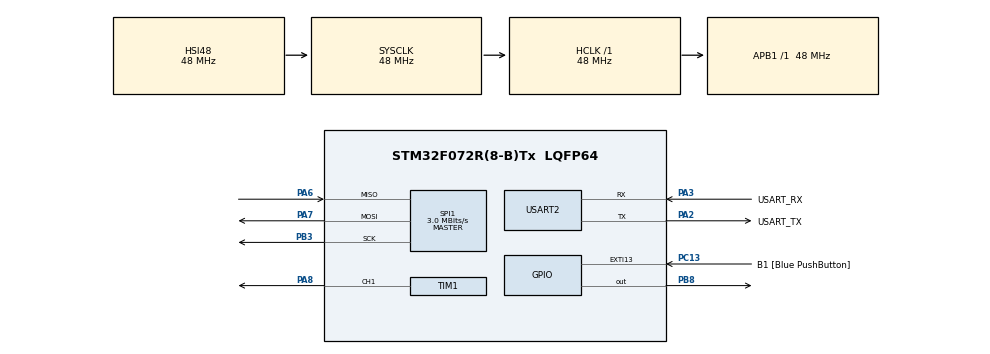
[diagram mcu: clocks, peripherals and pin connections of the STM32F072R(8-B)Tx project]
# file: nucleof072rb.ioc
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Mcu.Family=STM32F0
Mcu.Name=STM32F072R(8-B)Tx
Mcu.Package=LQFP64
PA13.GPIO_Label=TMS
PA13.Mode=Serial_Wire
PA13.Signal=SYS_SWDIO
PA14.GPIO_Label=TCK
PA14.Mode=Serial_Wire
PA14.Signal=SYS_SWCLK
PA2.GPIO_Label=USART_TX
PA2.GPIO_Mode=GPIO_MODE_AF_PP
PA2.GPIO_PuPd=GPIO_NOPULL
PA2.GPIO_Speed=GPIO_SPEED_FREQ_LOW
PA2.Mode=Asynchronous
PA2.Signal=USART2_TX
PA3.GPIO_Label=USART_RX
PA3.GPIO_Mode=GPIO_MODE_AF_PP
PA3.GPIO_PuPd=GPIO_NOPULL
PA3.GPIO_Speed=GPIO_SPEED_FREQ_LOW
PA3.Mode=Asynchronous
PA3.Signal=USART2_RX
PA6.Mode=Full_Duplex_Master
PA6.Signal=SPI1_MISO
PA7.Mode=Full_Duplex_Master
PA7.Signal=SPI1_MOSI
PA8.Signal=S_TIM1_CH1
PB3.Mode=Full_Duplex_Master
PB3.Signal=SPI1_SCK
PB8.Signal=GPIO_Output
PC13.GPIO_Label=B1 [Blue PushButton]
PC13.GPIO_ModeDefaultEXTI=GPIO_MODE_IT_FALLING
PC13.Signal=GPXTI13
PC14-OSC32_IN.Mode=LSE-External-Oscillator
PC14-OSC32_IN.Signal=RCC_OSC32_IN
PC15-OSC32_OUT.Mode=LSE-External-Oscillator
PC15-OSC32_OUT.Signal=RCC_OSC32_OUT
PF0-OSC_IN.Mode=HSE-External-Clock-Source
PF0-OSC_IN.Signal=RCC_OSC_IN
PF1-OSC_OUT.Signal=RCC_OSC_OUT
ProjectManager.HeapSize=0x200
ProjectManager.StackSize=0x400
ProjectManager.TargetToolchain=STM32CubeIDE
RCC.AHBFreq_Value=48000000
RCC.APB1Freq_Value=48000000
RCC.APB1TimFreq_Value=48000000
RCC.FLatency-AdvancedSettings=FLASH_LATENCY_1
RCC.HCLKFreq_Value=48000000
RCC.PLLDivider=RCC_PREDIV_DIV2
RCC.PLLMUL=RCC_PLL_MUL12
RCC.PREFETCH_ENABLE-AdvancedSettings=1
RCC.SYSCLKFreq_VALUE=48000000
RCC.SYSCLKSource=RCC_SYSCLKSOURCE_HSI48
SH.S_TIM1_CH1.0=TIM1_CH1,PWM Generation1 CH1
SPI1.BaudRatePrescaler=SPI_BAUDRATEPRESCALER_16
SPI1.CalculateBaudRate=3.0 MBits/s
SPI1.DataSize=SPI_DATASIZE_8BIT
SPI1.Direction=SPI_DIRECTION_2LINES
SPI1.Mode=SPI_MODE_MASTER
SPI1.VirtualType=VM_MASTER
TIM1.Channel-PWM\ Generation1\ CH1=TIM_CHANNEL_1
TIM1.Period=64000
TIM1.Prescaler=14
USART2.VirtualMode=VM_ASYNC
USART2.VirtualMode-Asynchronous=VM_ASYNC
VP_TIM1_VS_ClockSourceINT.Mode=Internal
board=NUCLEO-F072RB

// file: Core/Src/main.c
/* USER CODE BEGIN Header */
/**
  ******************************************************************************
  * @file           : main.c
  * @brief          : Main program body
  ******************************************************************************
  * @attention
  *
  * <h2><center>&copy; Copyright (c) 2021 STMicroelectronics.
  * All rights reserved.</center></h2>
  *
  * This software component is licensed by ST under BSD 3-Clause license,
  * the "License"; You may not use this file except in compliance with the
  * License. You may obtain a copy of the License at:
  *                        opensource.org/licenses/BSD-3-Clause
  *
  ******************************************************************************
  */
/* USER CODE END Header */
#include "main.h"
#include "spi.h"
#include "tim.h"
#include "usart.h"
#include "gpio.h"

void SystemClock_Config(void);

int main(void)
{
  /* USER CODE BEGIN 1 */
	uint8_t txDataBuffer[3] = {0x01, 0x80, 0x00}; // 0b1, 0b10000000, 0b0 to hex
	uint8_t rxDataBuffer[3];
	uint32_t minPeriod = __HAL_TIM_GET_AUTORELOAD(&htim1)*0.05;
  /* USER CODE END 1 */

  /* MCU Configuration--------------------------------------------------------*/

  /* Reset of all peripherals, Initializes the Flash interface and the Systick. */
  HAL_Init();

  /* Configure the system clock */
  SystemClock_Config();

  /* Initialize all configured peripherals */
  MX_GPIO_Init();
  MX_USART2_UART_Init();
  MX_SPI1_Init();
  MX_TIM1_Init();
  /* USER CODE BEGIN 2 */
  	HAL_GPIO_WritePin(GPIOB, GPIO_PIN_8, GPIO_PIN_SET); // set CS to high
  	__HAL_TIM_SET_COMPARE(&htim1, TIM_CHANNEL_1, minPeriod); // set compare register to 5%
  	HAL_TIM_PWM_Start(&htim1, TIM_CHANNEL_1);
  /* USER CODE END 2 */

  /* Infinite loop */
  /* USER CODE BEGIN WHILE */
  while (1)
  {
	 HAL_GPIO_WritePin(GPIOB, GPIO_PIN_8, GPIO_PIN_RESET); // pull down CS
	 HAL_SPI_TransmitReceive(&hspi1,txDataBuffer, rxDataBuffer, 3, HAL_MAX_DELAY);
	 HAL_GPIO_WritePin(GPIOB, GPIO_PIN_8, GPIO_PIN_SET);

	 uint16_t receivedData = (rxDataBuffer[1] << 8) | rxDataBuffer[2]; //combine both bytes
	 receivedData = addData & 0x3FF; // 0b0000011111111111 to hex

	 int dutyCycle = minPeriod + (receivedData / 1023.0)*minPeriod; //convert to timer count, 5-10%
	 __HAL_TIME_SET_COMPARE(&htim1, TIM_CHANNEL_1, dutyCycle);

	 HAL_Delay(10);
    /* USER CODE END WHILE */

  }
}

void SystemClock_Config(void)
{
  RCC_OscInitTypeDef RCC_OscInitStruct = {0};
  RCC_ClkInitTypeDef RCC_ClkInitStruct = {0};
  RCC_PeriphCLKInitTypeDef PeriphClkInit = {0};

  /** Initializes the RCC Oscillators according to the specified parameters
  * in the RCC_OscInitTypeDef structure.
  */
  RCC_OscInitStruct.OscillatorType = RCC_OSCILLATORTYPE_HSI48;
  RCC_OscInitStruct.HSI48State = RCC_HSI48_ON;
  RCC_OscInitStruct.PLL.PLLState = RCC_PLL_NONE;
  if (HAL_RCC_OscConfig(&RCC_OscInitStruct) != HAL_OK)
  {
    Error_Handler();
  }
  /** Initializes the CPU, AHB and APB buses clocks
  */
  RCC_ClkInitStruct.ClockType = RCC_CLOCKTYPE_HCLK|RCC_CLOCKTYPE_SYSCLK
                              |RCC_CLOCKTYPE_PCLK1;
  RCC_ClkInitStruct.SYSCLKSource = RCC_SYSCLKSOURCE_HSI48;
  RCC_ClkInitStruct.AHBCLKDivider = RCC_SYSCLK_DIV1;
  RCC_ClkInitStruct.APB1CLKDivider = RCC_HCLK_DIV1;

  if (HAL_RCC_ClockConfig(&RCC_ClkInitStruct, FLASH_LATENCY_1) != HAL_OK)
  {
    Error_Handler();
  }
  PeriphClkInit.PeriphClockSelection = RCC_PERIPHCLK_USART2;
  PeriphClkInit.Usart2ClockSelection = RCC_USART2CLKSOURCE_PCLK1;
  if (HAL_RCCEx_PeriphCLKConfig(&PeriphClkInit) != HAL_OK)
  {
    Error_Handler();
  }
}

void Error_Handler(void)
{
  __disable_irq();
  while (1)
  {
  }
}

/************************ (C) COPYRIGHT STMicroelectronics *****END OF FILE****/
